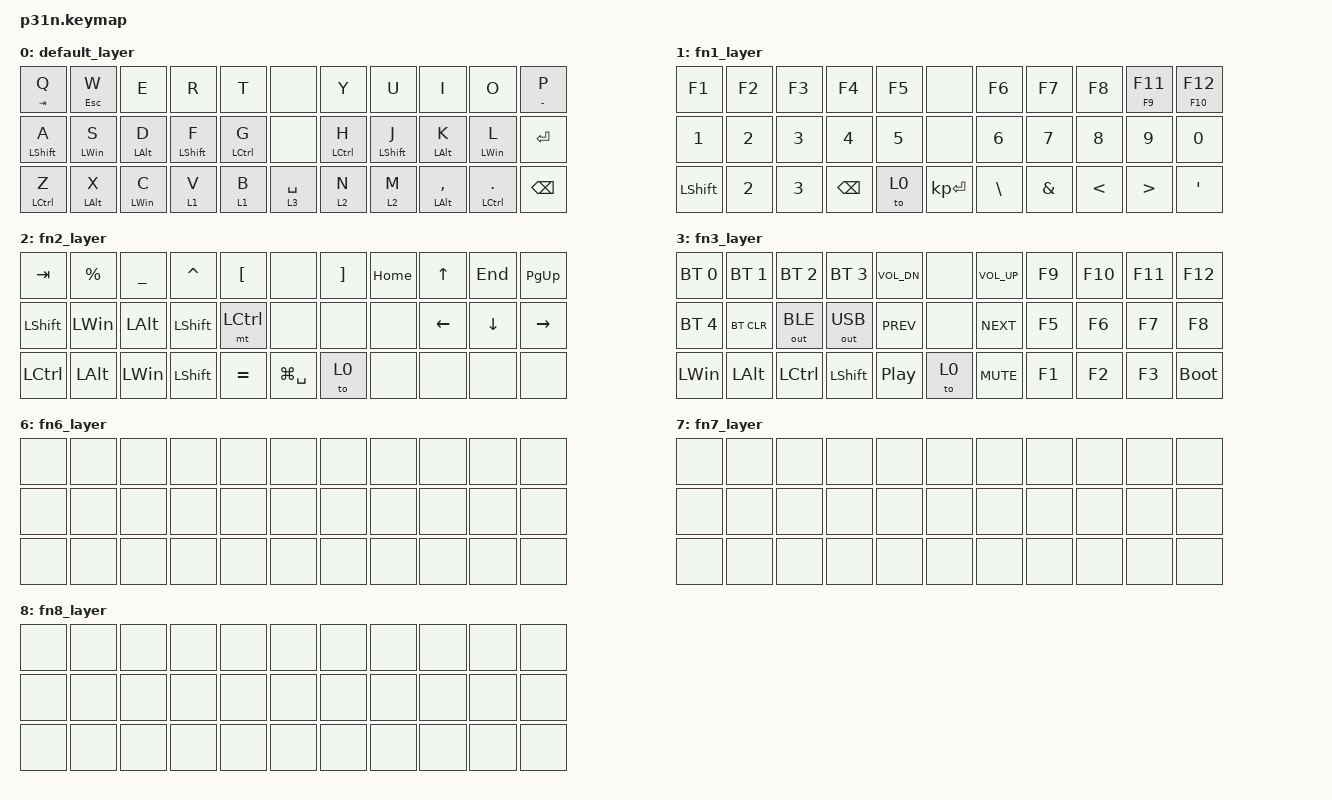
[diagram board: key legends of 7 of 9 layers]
/*
 * Copyright (c) 2020 The ZMK Contributors
 *
 * SPDX-License-Identifier: MIT
 */

#include <behaviors.dtsi>
#include <dt-bindings/zmk/keys.h>
#include <dt-bindings/zmk/rgb.h>
#include <dt-bindings/zmk/bt.h>
#include <dt-bindings/zmk/outputs.h>
#include <dt-bindings/zmk/ext_power.h>
#include <dt-bindings/zmk/mouse.h>

&mt {
    flavor = "balanced";
};

/ {
      combos {
        compatible = "zmk,combos";
      // W + E = ESC
        combo_esc {
            timeout-ms = <50>;
            key-positions = <1 2>; // WとEの位置番号に修正してください
            bindings = <&kp ESC>;
        };

        // S + D = Tab
        combo_tab {
            timeout-ms = <50>;
            key-positions = <12 13>;
            bindings = <&kp TAB>;
        };

        // D + F = BackSpace
        combo_bspc {
            timeout-ms = <50>;
            key-positions = <13 14>;
            bindings = <&kp BSPC>;
        };

        // X + C = ABC (英語入力 / 英数)
        combo_eng {
            timeout-ms = <50>;
            key-positions = <21 22>;
            bindings = <&kp LANG2>; // Windowsの場合は &kp INT_MUHENKAN を推奨
        };

        // F + J = Caps Word (左右をまたぐコンボ)
        combo_caps_word {
            timeout-ms = <50>;
            key-positions = <13 16>;
            bindings = <&caps_word>;
        };

        // U + I = 
        combo_minus {
            timeout-ms = <50>;
            key-positions = <8 9>;
            bindings = <&kp MINUS>;
        };

        // I + O = EQUAL
        combo_equal {
            timeout-ms = <50>;
            key-positions = <8 9>;
            bindings = <&kp EQUAL>;
        };

        // O + P = BSPC
        combo_backspace {
            timeout-ms = <50>;
            key-positions = <9 10>;
            bindings = <&kp BSPC>;
        };

        // K + L = しかくかっこはじめ
        combo_kl {
            timeout-ms = <50>;
            key-positions = <18 19>;
            bindings = <&kp LEFT_BRACKET>;
        };

        // L + ENT = しかくかっことじ
        combo_lenter {
            timeout-ms = <50>;
            key-positions = <19 20>;
            bindings = <&kp RIGHT_BRACKET>;
        };

        // M + , = slash
        combo_slash {
            timeout-ms = <50>;
            key-positions = <29 30>;
            bindings = <&kp SLASH>;
        };

        // ,+ . = backslash
        combo_backslash {
            timeout-ms = <50>;
            key-positions = <30 31>;
            bindings = <&kp BACKSLASH>;
        };

        // , +. = あいう (日本語入力 / かな)
        combo_kana {
            timeout-ms = <50>;
            key-positions = <31 32>;
            bindings = <&kp LANG1>; // Windowsの場合は &kp INT_HENKAN を推奨
        };
    };

      macros {
        xtips: xtips {
            compatible = "zmk,behavior-macro";
            label = "XTIPS";
            #binding-cells = <0>;
            bindings = <&kp LS(X) &kp KP_DOT &kp LS(T) &kp I &kp P &kp S>;
            wait-ms = <1>;
            tap-ms = <1>;
        };
      };

	keymap0: keymap {
		compatible = "zmk,keymap";

		default_layer {
            // |   Q   |   W   |   E   |   R   |   T   |    ----   |   Y   |   U   |   I    |   O    |   P   |
            // |   A   |   S   |   D   |   F   |   G   |    ----   |   H   |   J   |   K    |   L    |  Ent  |
            // | LG,Z  |  LA,X | LC,C  | LS,V  | LT1,B | LT3,SPACE | LT2,N | RS,M  | RS,TAb | RA,ESC | RG,BS | 
            bindings = <
            &mt TAB Q      &mt ESC W        &kp E         &kp R        &kp T       &none         &kp Y        &kp U         &kp I            &kp O          &mt MINUS P    
            &mt LSHFT A    &mt LWIN S       &mt LALT D    &mt LSHFT F  &mt LCTRL G &none         &mt LCTRL H  &mt LSHFT J   &mt LALT K       &mt LWIN L     &kp ENTER
            &mt LCTRL Z    &mt LALT X       &mt LWIN C    &lt 1 V      &lt 1 B     &lt 3 SPACE   &lt 2 N      &lt 2 M       &mt LALT COMMA  &mt LCTRL DOT   &kp BSPC
            >;
		};

		fn1_layer {
            bindings = <
            &kp F1    &kp F2    &kp F3    &kp F4     &kp F5        &none          &kp F6           &kp F7        &kp F8         &mt F9 F11     &mt F10 F12  
            &kp N1    &kp N2    &kp N3    &kp N4     &kp N5        &none          &kp N6           &kp N7        &kp N8         &kp N9         &kp N0
            &kp LSHFT &kp N2    &kp N3    &kp BSPC   &to 0         &kp KP_ENTER   &kp BSLH         &kp AMPS      &kp LT         &kp GT         &kp SQT        
             >;
		};

		fn2_layer {
            bindings = <
            &kp TAB    &kp PRCNT &kp UNDER &kp CARET  &kp LBKT         &none          &kp RBKT  &kp HOME    &kp UP      &kp END     &kp PG_UP  
            &kp LSHFT  &kp LWIN  &kp LALT  &kp LSHFT  &mt LCTRL        &none          &none     &none       &kp LEFT    &kp DOWN    &kp RIGHT
            &kp LCTRL  &kp LALT  &kp LWIN  &kp LSHFT  &kp EQUAL        &kp LG(SPACE)  &to 0     &none       &none       &none       &none      
            >;
		};

		fn3_layer {
            bindings = <
            &bt BT_SEL 0   &bt BT_SEL 1   &bt BT_SEL 2   &bt BT_SEL 3   &kp C_VOL_DN   &none   &kp C_VOL_UP   &kp F9   &kp F10   &kp F11   &kp F12   
            &bt BT_SEL 4   &bt BT_CLR     &out OUT_BLE   &out OUT_USB   &kp C_PREV     &none   &kp C_NEXT     &kp F5   &kp F6    &kp F7    &kp F8    
            &kp LWIN       &kp LALT       &kp LCTRL      &kp LSHFT      &kp C_PP       &to 0   &kp C_MUTE     &kp F1   &kp F2    &kp F3    &bootloader        
            >;
		};
		
		fn4_layer {
            bindings = <
            &to 0              &kp LS(LC(LA(W)))  &kp LS(LC(LA(E)))  &kp LS(LC(LA(R)))  &kp LS(LC(LA(T)))   &none   &kp LS(LC(LA(Y)))  &kp LS(LC(LA(U)))  &kp LS(LC(LA(I)))     &kp LS(LC(LA(O)))   &kp LS(LC(LA(P)))       
            &kp LS(LC(LA(A)))  &kp LS(LC(LA(S)))  &kp LS(LC(LA(D)))  &kp LS(LC(LA(F)))  &kp LS(LC(LA(G)))   &none   &kp LS(LC(LA(H)))  &kp LS(LC(LA(J)))  &kp LS(LC(LA(K)))     &kp LS(LC(LA(L)))   &kp LS(LC(LA(ENTER)))   
            &kp LS(LC(LA(Z)))  &kp LS(LC(LA(X)))  &kp LS(LC(LA(C)))  &kp LS(LC(LA(V)))  &kp LS(LC(LA(B)))   &mo 5   &kp LS(LC(LA(N)))  &kp LS(LC(LA(M)))  &kp LS(LC(LA(COMMA))) &kp LS(LC(LA(DOT))) &kp LS(LC(LA(BSPC)))        
            >;
		};

		fn5_layer {
            bindings = <
            &kp LA(LG(Q))  &kp LA(LG(W))  &kp LA(LG(E))  &kp LA(LG(R))  &kp LA(LG(T))   &none   &kp LA(LG(Y))  &kp LA(LG(U))  &kp LA(LG(I))   &kp LA(LG(O))         &kp LA(LG(P))      
            &kp LA(LG(A))  &kp LA(LG(S))  &kp LA(LG(D))  &kp LA(LG(F))  &kp LA(LG(G))   &none   &kp LA(LG(H))  &kp LA(LG(J))  &kp LA(LG(K))   &kp LA(LG(L))         &kp LA(LG(ENTER))  
            &kp K_CMENU    &kp INS        &kp SLCK       &kp KP_NLCK    &kp PAUSE_BREAK &to 0   &kp PSCRN      &xtips         &bootloader     &kp LS(LC(LA(LBRC)))  &kp LS(LC(LA(RBRC)))     
            >;
		};
		
		fn6_layer {
            bindings = <
            &none   &none   &none   &none    &none   &none   &none   &none   &none   &none   &none  
            &none   &none   &none   &none    &none   &none   &none   &none   &none   &none   &none  
            &none   &none   &none   &none    &none   &none   &none   &none   &none   &none   &none      
            >;
		};
		
		fn7_layer {
            bindings = <
            &none   &none   &none   &none    &none   &none   &none   &none   &none   &none   &none  
            &none   &none   &none   &none    &none   &none   &none   &none   &none   &none   &none  
            &none   &none   &none   &none    &none   &none   &none   &none   &none   &none   &none      
            >;
		};
		
		fn8_layer {
            bindings = <
            &none   &none   &none   &none    &none   &none   &none   &none   &none   &none   &none  
            &none   &none   &none   &none    &none   &none   &none   &none   &none   &none   &none  
            &none   &none   &none   &none    &none   &none   &none   &none   &none   &none   &none      
            >;
		};
	};
};
